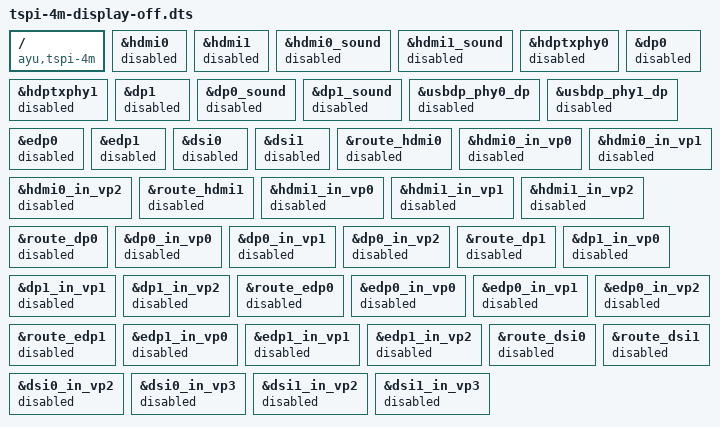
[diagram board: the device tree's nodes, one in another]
/dts-v1/;
/plugin/;
#include <dt-bindings/clock/rk3588-cru.h>
#include <dt-bindings/gpio/gpio.h>
#include <dt-bindings/interrupt-controller/irq.h>
#include <dt-bindings/pinctrl/rockchip.h>
#include <dt-bindings/display/drm_mipi_dsi.h>

/ {
	compatible = "ayu,tspi-4m", "rockchip,rk3588";
};

&hdmi0 { status = "disabled"; };
&hdmi1 { status = "disabled"; };
&hdmi0_sound { status = "disabled"; };
&hdmi1_sound { status = "disabled"; };
&hdptxphy0 { status = "disabled"; };
&hdptxphy1 { status = "disabled"; };
&dp0 { status = "disabled"; };
&dp1 { status = "disabled"; };
&dp0_sound { status = "disabled"; };
&dp1_sound { status = "disabled"; };
&usbdp_phy0_dp { status = "disabled"; };
&usbdp_phy1_dp { status = "disabled"; };
&edp0 { status = "disabled"; };
&edp1 { status = "disabled"; };
&dsi0 { status = "disabled"; };
&dsi1 { status = "disabled"; };
&route_hdmi0 { status = "disabled"; };
&hdmi0_in_vp0 { status = "disabled"; };
&hdmi0_in_vp1 { status = "disabled"; };
&hdmi0_in_vp2 { status = "disabled"; };
&route_hdmi1 { status = "disabled"; };
&hdmi1_in_vp0 { status = "disabled"; };
&hdmi1_in_vp1 { status = "disabled"; };
&hdmi1_in_vp2 { status = "disabled"; };
&route_dp0 { status = "disabled"; };
&dp0_in_vp0 { status = "disabled"; };
&dp0_in_vp1 { status = "disabled"; };
&dp0_in_vp2 { status = "disabled"; };
&route_dp1 { status = "disabled"; };
&dp1_in_vp0 { status = "disabled"; };
&dp1_in_vp1 { status = "disabled"; };
&dp1_in_vp2 { status = "disabled"; };
&route_edp0 { status = "disabled"; };
&edp0_in_vp0 { status = "disabled"; };
&edp0_in_vp1 { status = "disabled"; };
&edp0_in_vp2 { status = "disabled"; };
&route_edp1 { status = "disabled"; };
&edp1_in_vp0 { status = "disabled"; };
&edp1_in_vp1 { status = "disabled"; };
&edp1_in_vp2 { status = "disabled"; };
&route_dsi0 { status = "disabled"; };
&dsi0_in_vp2 { status = "disabled"; };
&dsi0_in_vp3 { status = "disabled"; };
&route_dsi1 { status = "disabled"; };
&dsi1_in_vp2 { status = "disabled"; };
&dsi1_in_vp3 { status = "disabled"; };
